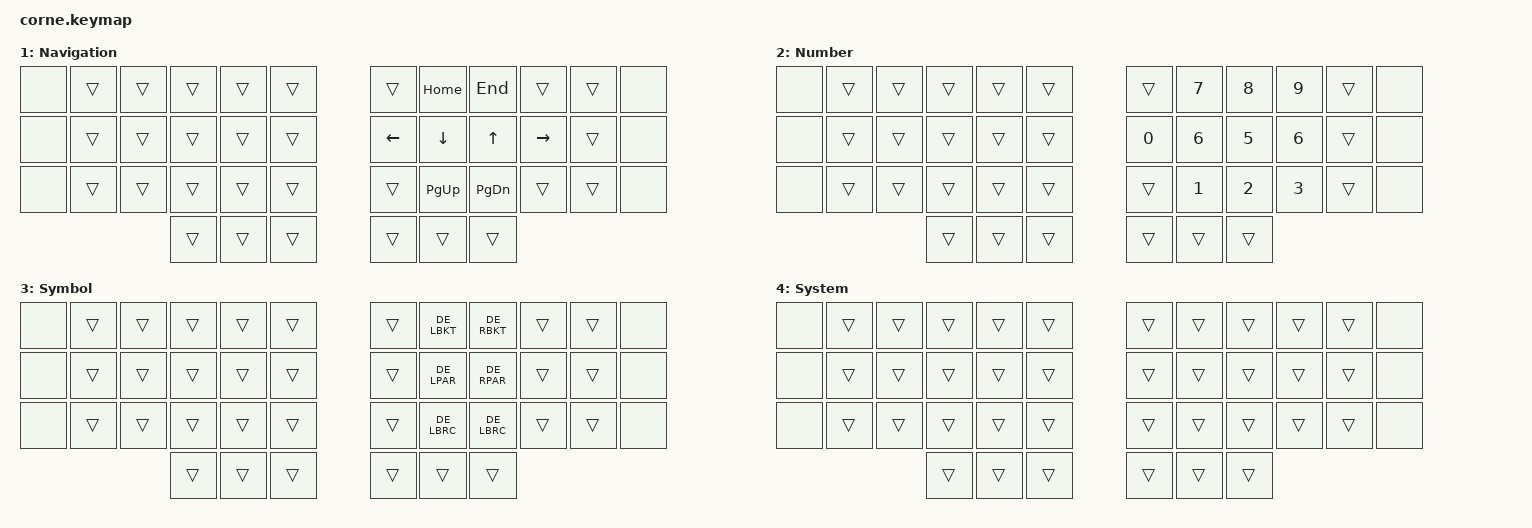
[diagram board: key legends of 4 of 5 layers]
#include <behaviors.dtsi>
#include <dt-bindings/zmk/keys.h>
#include <locale/keys_de.h>


/**
 * Corne 6-columns (42 keys) Key Matrix
 * ------------------------------------
 *      ╭────────────────────────┬────────────────────────╮
 *      │  0   1   2   3   4   5 │  6   7   8   9  10  11 │
 *      │ 12  13  14  15  16  17 │ 18  19  20  21  22  23 │
 *      │ 24  25  26  27  28  29 │ 30  31  32  33  34  35 │
 *      ╰───────────╮ 36  37  38 │ 39  40  41 ╭───────────╯
 *                  ╰────────────┴────────────╯
 *
 * Corne 6-columns (42 keys) Key Labels
 * ------------------------------------
 *     ╭─────────────────────────┬─────────────────────────╮
 *     │ LT5 LT4 LT3 LT2 LT1 LT0 │ RT0 RT1 RT2 RT3 RT4 RT5 │
 *     │ LM5 LM4 LM3 LM2 LM1 LM0 │ RM0 RM1 RM2 RM3 RM4 RM5 │
 *     │ LB5 LB4 LB3 LB2 LB1 LB0 │ RB0 RB1 RB2 RB3 RB4 RB5 │
 *     ╰───────────╮ LF3 LF1 LF0 │ RF0 RF1 RF3 ╭───────────╯
 *                 ╰─────────────┴─────────────╯
 */

#define LT0  5  // left-top row
#define LT1  4
#define LT2  3
#define LT3  2
#define LT4  1
#define LT5  0

#define RT0  6  // right-top row
#define RT1  7
#define RT2  8
#define RT3  9
#define RT4 10
#define RT5 11

#define LM0 17  // left-middle row
#define LM1 16
#define LM2 15
#define LM3 14
#define LM4 13
#define LM5 12

#define RM0 18  // right-middle row
#define RM1 19
#define RM2 20
#define RM3 21
#define RM4 22
#define RM5 23

#define LB0 29  // left-bottom row
#define LB1 28
#define LB2 27
#define LB3 26
#define LB4 25
#define LB5 24

#define RB0 30  // right-bottom row
#define RB1 31
#define RB2 32
#define RB3 33
#define RB4 34
#define RB5 35

#define LF0 38  // left thumb keys
#define LF1 37
#define LF2 36

#define RF0 39  // right thumb keys
#define RF1 40
#define RF2 41

// All keys on the left side of the keyboard excluding thumb keys
#define KEYS_L LT0 LT1 LT2 LT3 LT4 LT5 LM0 LM1 LM2 LM3 LM4 LM5 LB0 LB1 LB2 LB3 LB4 LB5

// All keys on the right side of the keyboard excluding thumb keys
#define KEYS_R RT0 RT1 RT2 RT3 RT4 RT5 RM0 RM1 RM2 RM3 RM4 RM5 RB0 RB1 RB2 RB3 RB4 RB5

// Thumb cluster keys from the left side of the keyboard
#define THUMB_L LF2 LF1 LF0

// Thumb cluster keys from the right side of the keyboard
#define THUMB_R RF0 RF1 RF2

// All thumb cluster keys
#define THUMBS THUMB_L THUMB_R

// Layers
#define BASE 0
#define NAV 1
#define NUM 2
#define SYM 3
#define SYS 4


/ {
    behaviors {
        hml: home_row_mod_left {
            compatible = "zmk,behavior-hold-tap";
            #binding-cells = <2>;
            flavor = "balanced";
            require-prior-idle-ms = <150>;
            tapping-term-ms = <280>;
            quick-tap-ms = <175>;
            bindings = <&kp>, <&kp>;
            hold-trigger-key-positions = <KEYS_L THUMBS>;
            hold-trigger-on-release;
        };
        hmr: home_row_mod_right {
            compatible = "zmk,behavior-hold-tap";
            #binding-cells = <2>;
            flavor = "balanced";
            require-prior-idle-ms = <150>;
            tapping-term-ms = <280>;
            quick-tap-ms = <175>;
            bindings = <&kp>, <&kp>;
            hold-trigger-key-positions = <KEYS_R THUMBS>;
            hold-trigger-on-release;
        };

        bspc_del: backspace_delete {
            compatible = "zmk,behavior-mod-morph";
            #binding-cells = <0>;
            bindings = <&kp BACKSPACE>, <&kp DELETE>;
            mods = <(MOD_LSFT)>;
        };
    };

    keymap {
        compatible = "zmk,keymap";

            base {
                display-name = "Base";
                bindings = <
&none  &kp DE_Q         &kp DE_W        &kp DE_E        &kp DE_R         &kp DE_T    &kp DE_Z  &kp DE_U         &kp DE_I        &kp DE_O        &kp DE_P             &none
&none  &hml LSHFT DE_A  &hml LALT DE_S  &hml LGUI DE_D  &hml LCTRL DE_F  &kp DE_G    &kp DE_H  &hmr RCTRL DE_J  &hmr RGUI DE_K  &hmr RALT DE_L  &hmr RSHFT DE_QMARK  &none
&none  &kp DE_Y         &kp DE_X        &kp DE_C        &kp DE_V         &kp DE_B    &kp DE_N  &kp DE_M         &kp DE_COMMA    &kp DE_DOT      &kp DE_MINUS         &none
                                            &mo NUM   &lt SYM TAB   &lt LSHFT ESC    &mt LC(LS(LA(LGUI))) RET   &lt NAV SPACE   &lt SYS &bspc_del
                >;
            };
 
            nav {
                display-name = "Navigation";
                bindings = <
&none  &trans  &trans  &trans  &trans  &trans    &trans    &kp HOME   &kp END    &trans     &trans  &none
&none  &trans  &trans  &trans  &trans  &trans    &kp LEFT  &kp DOWN   &kp UP     &kp RIGHT  &trans  &none
&none  &trans  &trans  &trans  &trans  &trans    &trans    &kp PG_UP  &kp PG_DN  &trans     &trans  &none
                       &trans  &trans  &trans    &trans    &trans     &trans
                >;
            };

            num {
                display-name = "Number";
                bindings = <
&none  &trans  &trans  &trans  &trans  &trans    &trans  &kp N7  &kp N8  &kp N9  &trans  &none
&none  &trans  &trans  &trans  &trans  &trans    &kp N0  &kp N6  &kp N5  &kp N6  &trans  &none
&none  &trans  &trans  &trans  &trans  &trans    &trans  &kp N1  &kp N2  &kp N3  &trans  &none
                       &trans  &trans  &trans    &trans  &trans  &trans
                >;
            };

            sym {
                display-name = "Symbol";
                bindings = <
&none  &trans  &trans  &trans  &trans  &trans    &trans  &kp DE_LBKT  &kp DE_RBKT  &trans  &trans  &none
&none  &trans  &trans  &trans  &trans  &trans    &trans  &kp DE_LPAR  &kp DE_RPAR  &trans  &trans  &none
&none  &trans  &trans  &trans  &trans  &trans    &trans  &kp DE_LBRC  &kp DE_LBRC  &trans  &trans  &none
                       &trans  &trans  &trans    &trans  &trans  &trans
                >;
            };

            sys {
                display-name = "System";
                bindings = <
&none  &trans  &trans  &trans  &trans  &trans    &trans  &trans  &trans  &trans  &trans  &none
&none  &trans  &trans  &trans  &trans  &trans    &trans  &trans  &trans  &trans  &trans  &none
&none  &trans  &trans  &trans  &trans  &trans    &trans  &trans  &trans  &trans  &trans  &none
                       &trans  &trans  &trans    &trans  &trans  &trans
                >;
            };
    };
};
